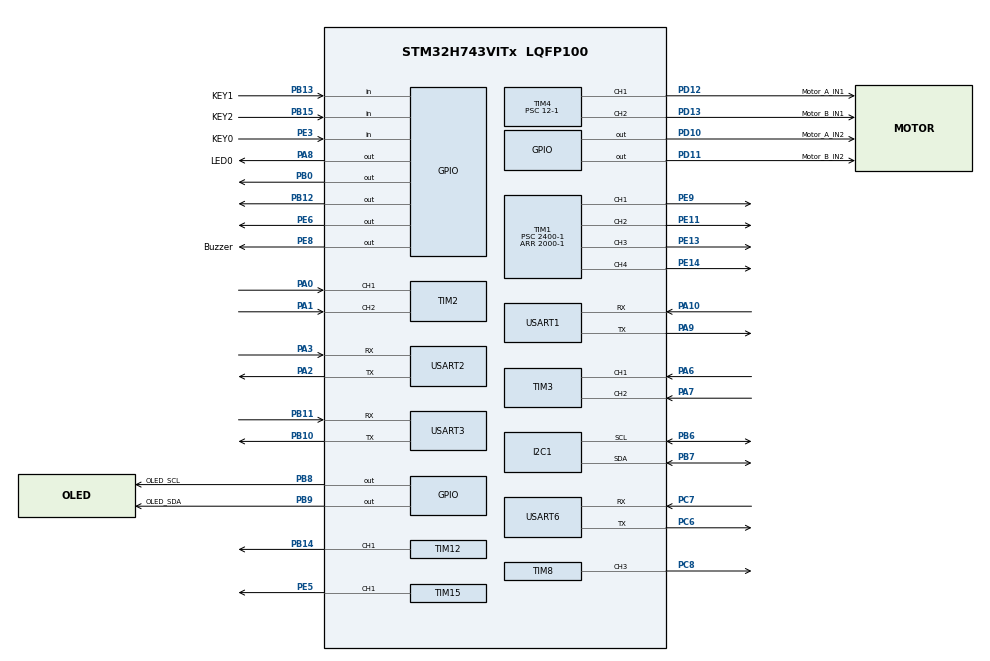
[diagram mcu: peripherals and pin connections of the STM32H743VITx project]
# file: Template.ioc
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CORTEX_M7.AccessPermission-Cortex_Memory_Protection_Unit_Region0_Settings=MPU_REGION_FULL_ACCESS
CORTEX_M7.AccessPermission-Cortex_Memory_Protection_Unit_Region1_Settings=MPU_REGION_FULL_ACCESS
CORTEX_M7.AccessPermission-Cortex_Memory_Protection_Unit_Region2_Settings=MPU_REGION_FULL_ACCESS
CORTEX_M7.AccessPermission-Cortex_Memory_Protection_Unit_Region3_Settings=MPU_REGION_FULL_ACCESS
CORTEX_M7.AccessPermission-Cortex_Memory_Protection_Unit_Region4_Settings=MPU_REGION_FULL_ACCESS
CORTEX_M7.BaseAddress-Cortex_Memory_Protection_Unit_Region0_Settings=0x24000000
CORTEX_M7.BaseAddress-Cortex_Memory_Protection_Unit_Region1_Settings=0x30000000
CORTEX_M7.BaseAddress-Cortex_Memory_Protection_Unit_Region2_Settings=0x30020000
CORTEX_M7.BaseAddress-Cortex_Memory_Protection_Unit_Region3_Settings=0x30040000
CORTEX_M7.BaseAddress-Cortex_Memory_Protection_Unit_Region4_Settings=0x38000000
CORTEX_M7.CPU_DCache=Enabled
CORTEX_M7.CPU_ICache=Enabled
CORTEX_M7.Enable-Cortex_Memory_Protection_Unit_Region0_Settings=MPU_REGION_ENABLE
CORTEX_M7.Enable-Cortex_Memory_Protection_Unit_Region1_Settings=MPU_REGION_ENABLE
CORTEX_M7.Enable-Cortex_Memory_Protection_Unit_Region2_Settings=MPU_REGION_ENABLE
CORTEX_M7.Enable-Cortex_Memory_Protection_Unit_Region3_Settings=MPU_REGION_ENABLE
CORTEX_M7.Enable-Cortex_Memory_Protection_Unit_Region4_Settings=MPU_REGION_ENABLE
CORTEX_M7.IsBufferable-Cortex_Memory_Protection_Unit_Region0_Settings=MPU_ACCESS_BUFFERABLE
CORTEX_M7.IsCacheable-Cortex_Memory_Protection_Unit_Region0_Settings=MPU_ACCESS_CACHEABLE
CORTEX_M7.MPU_Control=MPU_PRIVILEGED_DEFAULT
CORTEX_M7.Size-Cortex_Memory_Protection_Unit_Region0_Settings=MPU_REGION_SIZE_512KB
CORTEX_M7.Size-Cortex_Memory_Protection_Unit_Region1_Settings=MPU_REGION_SIZE_128KB
CORTEX_M7.Size-Cortex_Memory_Protection_Unit_Region2_Settings=MPU_REGION_SIZE_128KB
CORTEX_M7.Size-Cortex_Memory_Protection_Unit_Region3_Settings=MPU_REGION_SIZE_32KB
CORTEX_M7.Size-Cortex_Memory_Protection_Unit_Region4_Settings=MPU_REGION_SIZE_64KB
CORTEX_M7.TypeExtField-Cortex_Memory_Protection_Unit_Region0_Settings=MPU_TEX_LEVEL1
CORTEX_M7.TypeExtField-Cortex_Memory_Protection_Unit_Region1_Settings=MPU_TEX_LEVEL1
CORTEX_M7.TypeExtField-Cortex_Memory_Protection_Unit_Region2_Settings=MPU_TEX_LEVEL1
CORTEX_M7.TypeExtField-Cortex_Memory_Protection_Unit_Region3_Settings=MPU_TEX_LEVEL1
CORTEX_M7.TypeExtField-Cortex_Memory_Protection_Unit_Region4_Settings=MPU_TEX_LEVEL1
Dma.Request0=USART2_RX
Dma.Request1=USART2_TX
Dma.Request2=USART1_RX
Dma.Request3=USART1_TX
Dma.Request4=USART3_RX
Dma.Request5=USART3_TX
Dma.Request6=USART6_RX
Dma.Request7=USART6_TX
Dma.USART1_RX.2.Direction=DMA_PERIPH_TO_MEMORY
Dma.USART1_RX.2.EventEnable=DISABLE
Dma.USART1_RX.2.FIFOMode=DMA_FIFOMODE_DISABLE
Dma.USART1_RX.2.Instance=DMA1_Stream2
Dma.USART1_RX.2.MemDataAlignment=DMA_MDATAALIGN_BYTE
Dma.USART1_RX.2.MemInc=DMA_MINC_ENABLE
Dma.USART1_RX.2.Mode=DMA_NORMAL
Dma.USART1_RX.2.PeriphDataAlignment=DMA_PDATAALIGN_BYTE
Dma.USART1_RX.2.PeriphInc=DMA_PINC_DISABLE
Dma.USART1_RX.2.Polarity=HAL_DMAMUX_REQ_GEN_RISING
Dma.USART1_RX.2.Priority=DMA_PRIORITY_HIGH
Dma.USART1_RX.2.RequestNumber=1
Dma.USART1_RX.2.SignalID=NONE
Dma.USART1_RX.2.SyncEnable=DISABLE
Dma.USART1_RX.2.SyncPolarity=HAL_DMAMUX_SYNC_NO_EVENT
Dma.USART1_RX.2.SyncRequestNumber=1
Dma.USART1_RX.2.SyncSignalID=NONE
Dma.USART1_TX.3.Direction=DMA_MEMORY_TO_PERIPH
Dma.USART1_TX.3.EventEnable=DISABLE
Dma.USART1_TX.3.FIFOMode=DMA_FIFOMODE_DISABLE
Dma.USART1_TX.3.Instance=DMA1_Stream3
Dma.USART1_TX.3.MemDataAlignment=DMA_MDATAALIGN_BYTE
Dma.USART1_TX.3.MemInc=DMA_MINC_ENABLE
Dma.USART1_TX.3.Mode=DMA_NORMAL
Dma.USART1_TX.3.PeriphDataAlignment=DMA_PDATAALIGN_BYTE
Dma.USART1_TX.3.PeriphInc=DMA_PINC_DISABLE
Dma.USART1_TX.3.Polarity=HAL_DMAMUX_REQ_GEN_RISING
Dma.USART1_TX.3.Priority=DMA_PRIORITY_HIGH
Dma.USART1_TX.3.RequestNumber=1
Dma.USART1_TX.3.SignalID=NONE
Dma.USART1_TX.3.SyncEnable=DISABLE
Dma.USART1_TX.3.SyncPolarity=HAL_DMAMUX_SYNC_NO_EVENT
Dma.USART1_TX.3.SyncRequestNumber=1
Dma.USART1_TX.3.SyncSignalID=NONE
Dma.USART2_RX.0.Direction=DMA_PERIPH_TO_MEMORY
Dma.USART2_RX.0.EventEnable=DISABLE
Dma.USART2_RX.0.FIFOMode=DMA_FIFOMODE_DISABLE
Dma.USART2_RX.0.Instance=DMA1_Stream0
Dma.USART2_RX.0.MemDataAlignment=DMA_MDATAALIGN_BYTE
Dma.USART2_RX.0.MemInc=DMA_MINC_ENABLE
Dma.USART2_RX.0.Mode=DMA_NORMAL
Dma.USART2_RX.0.PeriphDataAlignment=DMA_PDATAALIGN_BYTE
Dma.USART2_RX.0.PeriphInc=DMA_PINC_DISABLE
Dma.USART2_RX.0.Polarity=HAL_DMAMUX_REQ_GEN_RISING
Dma.USART2_RX.0.Priority=DMA_PRIORITY_HIGH
Dma.USART2_RX.0.RequestNumber=1
Dma.USART2_RX.0.SignalID=NONE
Dma.USART2_RX.0.SyncEnable=DISABLE
Dma.USART2_RX.0.SyncPolarity=HAL_DMAMUX_SYNC_NO_EVENT
Dma.USART2_RX.0.SyncRequestNumber=1
Dma.USART2_RX.0.SyncSignalID=NONE
Dma.USART2_TX.1.Direction=DMA_MEMORY_TO_PERIPH
Dma.USART2_TX.1.EventEnable=DISABLE
Dma.USART2_TX.1.FIFOMode=DMA_FIFOMODE_DISABLE
Dma.USART2_TX.1.Instance=DMA1_Stream1
Dma.USART2_TX.1.MemDataAlignment=DMA_MDATAALIGN_BYTE
Dma.USART2_TX.1.MemInc=DMA_MINC_ENABLE
Dma.USART2_TX.1.Mode=DMA_NORMAL
Dma.USART2_TX.1.PeriphDataAlignment=DMA_PDATAALIGN_BYTE
Dma.USART2_TX.1.PeriphInc=DMA_PINC_DISABLE
Dma.USART2_TX.1.Polarity=HAL_DMAMUX_REQ_GEN_RISING
Dma.USART2_TX.1.Priority=DMA_PRIORITY_HIGH
Dma.USART2_TX.1.RequestNumber=1
Dma.USART2_TX.1.SignalID=NONE
Dma.USART2_TX.1.SyncEnable=DISABLE
Dma.USART2_TX.1.SyncPolarity=HAL_DMAMUX_SYNC_NO_EVENT
Dma.USART2_TX.1.SyncRequestNumber=1
Dma.USART2_TX.1.SyncSignalID=NONE
Dma.USART3_RX.4.Direction=DMA_PERIPH_TO_MEMORY
Dma.USART3_RX.4.EventEnable=DISABLE
Dma.USART3_RX.4.FIFOMode=DMA_FIFOMODE_DISABLE
Dma.USART3_RX.4.Instance=DMA1_Stream4
Dma.USART3_RX.4.MemDataAlignment=DMA_MDATAALIGN_BYTE
Dma.USART3_RX.4.MemInc=DMA_MINC_ENABLE
Dma.USART3_RX.4.Mode=DMA_NORMAL
Dma.USART3_RX.4.PeriphDataAlignment=DMA_PDATAALIGN_BYTE
Dma.USART3_RX.4.PeriphInc=DMA_PINC_DISABLE
Dma.USART3_RX.4.Polarity=HAL_DMAMUX_REQ_GEN_RISING
Dma.USART3_RX.4.Priority=DMA_PRIORITY_LOW
Dma.USART3_RX.4.RequestNumber=1
Dma.USART3_RX.4.SignalID=NONE
Dma.USART3_RX.4.SyncEnable=DISABLE
Dma.USART3_RX.4.SyncPolarity=HAL_DMAMUX_SYNC_NO_EVENT
Dma.USART3_RX.4.SyncRequestNumber=1
Dma.USART3_RX.4.SyncSignalID=NONE
Dma.USART3_TX.5.Direction=DMA_MEMORY_TO_PERIPH
Dma.USART3_TX.5.EventEnable=DISABLE
Dma.USART3_TX.5.FIFOMode=DMA_FIFOMODE_DISABLE
Dma.USART3_TX.5.Instance=DMA1_Stream5
Dma.USART3_TX.5.MemDataAlignment=DMA_MDATAALIGN_BYTE
Dma.USART3_TX.5.MemInc=DMA_MINC_ENABLE
Dma.USART3_TX.5.Mode=DMA_NORMAL
Dma.USART3_TX.5.PeriphDataAlignment=DMA_PDATAALIGN_BYTE
Dma.USART3_TX.5.PeriphInc=DMA_PINC_DISABLE
Dma.USART3_TX.5.Polarity=HAL_DMAMUX_REQ_GEN_RISING
Dma.USART3_TX.5.Priority=DMA_PRIORITY_LOW
Dma.USART3_TX.5.RequestNumber=1
Dma.USART3_TX.5.SignalID=NONE
Dma.USART3_TX.5.SyncEnable=DISABLE
Dma.USART3_TX.5.SyncPolarity=HAL_DMAMUX_SYNC_NO_EVENT
Dma.USART3_TX.5.SyncRequestNumber=1
Dma.USART3_TX.5.SyncSignalID=NONE
Dma.USART6_RX.6.Direction=DMA_PERIPH_TO_MEMORY
Dma.USART6_RX.6.EventEnable=DISABLE
Dma.USART6_RX.6.FIFOMode=DMA_FIFOMODE_DISABLE
Dma.USART6_RX.6.Instance=DMA1_Stream6
Dma.USART6_RX.6.MemDataAlignment=DMA_MDATAALIGN_BYTE
Dma.USART6_RX.6.MemInc=DMA_MINC_ENABLE
Dma.USART6_RX.6.Mode=DMA_NORMAL
Dma.USART6_RX.6.PeriphDataAlignment=DMA_PDATAALIGN_BYTE
Dma.USART6_RX.6.PeriphInc=DMA_PINC_DISABLE
Dma.USART6_RX.6.Polarity=HAL_DMAMUX_REQ_GEN_RISING
Dma.USART6_RX.6.Priority=DMA_PRIORITY_LOW
Dma.USART6_RX.6.RequestNumber=1
Dma.USART6_RX.6.SignalID=NONE
Dma.USART6_RX.6.SyncEnable=DISABLE
Dma.USART6_RX.6.SyncPolarity=HAL_DMAMUX_SYNC_NO_EVENT
Dma.USART6_RX.6.SyncRequestNumber=1
Dma.USART6_RX.6.SyncSignalID=NONE
Dma.USART6_TX.7.Direction=DMA_MEMORY_TO_PERIPH
Dma.USART6_TX.7.EventEnable=DISABLE
Dma.USART6_TX.7.FIFOMode=DMA_FIFOMODE_DISABLE
Dma.USART6_TX.7.Instance=DMA2_Stream7
Dma.USART6_TX.7.MemDataAlignment=DMA_MDATAALIGN_BYTE
Dma.USART6_TX.7.MemInc=DMA_MINC_ENABLE
Dma.USART6_TX.7.Mode=DMA_NORMAL
Dma.USART6_TX.7.PeriphDataAlignment=DMA_PDATAALIGN_BYTE
Dma.USART6_TX.7.PeriphInc=DMA_PINC_DISABLE
Dma.USART6_TX.7.Polarity=HAL_DMAMUX_REQ_GEN_RISING
Dma.USART6_TX.7.Priority=DMA_PRIORITY_LOW
Dma.USART6_TX.7.RequestNumber=1
Dma.USART6_TX.7.SignalID=NONE
Dma.USART6_TX.7.SyncEnable=DISABLE
Dma.USART6_TX.7.SyncPolarity=HAL_DMAMUX_SYNC_NO_EVENT
Dma.USART6_TX.7.SyncRequestNumber=1
Dma.USART6_TX.7.SyncSignalID=NONE
I2C1.Timing=0x307075B1
Mcu.Family=STM32H7
Mcu.Name=STM32H743VITx
Mcu.Package=LQFP100
NVIC.DMA1_Stream0_IRQn=true\:0\:0\:false\:false\:true\:false\:true\:true
NVIC.DMA1_Stream1_IRQn=true\:0\:0\:false\:false\:true\:false\:true\:true
NVIC.DMA1_Stream2_IRQn=true\:0\:0\:false\:false\:true\:false\:true\:true
NVIC.DMA1_Stream3_IRQn=true\:0\:0\:false\:false\:true\:false\:true\:true
NVIC.DMA1_Stream4_IRQn=true\:0\:0\:false\:false\:true\:false\:true\:true
NVIC.DMA1_Stream5_IRQn=true\:0\:0\:false\:false\:true\:false\:true\:true
NVIC.DMA1_Stream6_IRQn=true\:0\:0\:false\:false\:true\:false\:true\:true
NVIC.DMA2_Stream7_IRQn=true\:0\:0\:false\:false\:true\:false\:true\:true
NVIC.PriorityGroup=NVIC_PRIORITYGROUP_4
NVIC.TIM15_IRQn=true\:0\:0\:false\:false\:true\:true\:true\:true
NVIC.TIM16_IRQn=true\:0\:0\:false\:false\:true\:true\:true\:true
NVIC.TIM17_IRQn=true\:0\:0\:false\:false\:true\:true\:true\:true
NVIC.TIM6_DAC_IRQn=true\:0\:0\:false\:false\:true\:true\:true\:true
NVIC.TIM8_BRK_TIM12_IRQn=true\:0\:0\:false\:false\:true\:true\:true\:true
NVIC.USART1_IRQn=true\:0\:0\:false\:false\:true\:true\:true\:true
NVIC.USART2_IRQn=true\:0\:0\:false\:false\:true\:true\:true\:true
NVIC.USART3_IRQn=true\:0\:0\:false\:false\:true\:true\:true\:true
NVIC.USART6_IRQn=true\:0\:0\:false\:false\:true\:true\:true\:true
PA0.Signal=S_TIM2_CH1_ETR
PA1.Signal=S_TIM2_CH2
PA10.Mode=Asynchronous
PA10.Signal=USART1_RX
PA13\ (JTMS/SWDIO).Mode=Serial_Wire
PA13\ (JTMS/SWDIO).Signal=DEBUG_JTMS-SWDIO
PA14\ (JTCK/SWCLK).Mode=Serial_Wire
PA14\ (JTCK/SWCLK).Signal=DEBUG_JTCK-SWCLK
PA2.Mode=Asynchronous
PA2.Signal=USART2_TX
PA3.Mode=Asynchronous
PA3.Signal=USART2_RX
PA6.Signal=S_TIM3_CH1
PA7.Signal=S_TIM3_CH2
PA8.GPIO_Label=LED0
PA8.GPIO_ModeDefaultOutputPP=GPIO_MODE_OUTPUT_PP
PA8.GPIO_PuPd=GPIO_NOPULL
PA8.GPIO_Speed=GPIO_SPEED_FREQ_LOW
PA8.PinState=GPIO_PIN_RESET
PA8.Signal=GPIO_Output
PA9.Mode=Asynchronous
PA9.Signal=USART1_TX
PB0.PinState=GPIO_PIN_SET
PB0.Signal=GPIO_Output
PB10.Mode=Asynchronous
PB10.Signal=USART3_TX
PB11.Mode=Asynchronous
PB11.Signal=USART3_RX
PB12.GPIO_Speed=GPIO_SPEED_FREQ_HIGH
PB12.Signal=GPIO_Output
PB13.GPIO_Label=KEY1
PB13.GPIO_PuPd=GPIO_PULLUP
PB13.Signal=GPIO_Input
PB14.Signal=S_TIM12_CH1
PB15.GPIO_Label=KEY2
PB15.GPIO_PuPd=GPIO_PULLUP
PB15.Signal=GPIO_Input
PB6.Mode=I2C
PB6.Signal=I2C1_SCL
PB7.Mode=I2C
PB7.Signal=I2C1_SDA
PB8.GPIO_FM8=__NULL
PB8.GPIO_Label=OLED_SCL
PB8.GPIO_ModeDefaultOutputPP=GPIO_MODE_OUTPUT_PP
PB8.GPIO_PuPd=GPIO_NOPULL
PB8.GPIO_Speed=GPIO_SPEED_FREQ_HIGH
PB8.PinState=GPIO_PIN_RESET
PB8.Signal=GPIO_Output
PB9.GPIO_FM9=__NULL
PB9.GPIO_Label=OLED_SDA
PB9.GPIO_ModeDefaultOutputPP=GPIO_MODE_OUTPUT_PP
PB9.GPIO_PuPd=GPIO_NOPULL
PB9.GPIO_Speed=GPIO_SPEED_FREQ_HIGH
PB9.PinState=GPIO_PIN_RESET
PB9.Signal=GPIO_Output
PC6.Mode=Asynchronous
PC6.Signal=USART6_TX
PC7.Mode=Asynchronous
PC7.Signal=USART6_RX
PC8.Signal=S_TIM8_CH3
PD10.GPIO_Label=Motor_A_IN2
PD10.Signal=GPIO_Output
PD11.GPIO_Label=Motor_B_IN2
PD11.Signal=GPIO_Output
PD12.GPIO_Label=Motor_A_IN1
PD12.Signal=S_TIM4_CH1
PD13.GPIO_Label=Motor_B_IN1
PD13.Signal=S_TIM4_CH2
PE11.Signal=S_TIM1_CH2
PE13.Signal=S_TIM1_CH3
PE14.Signal=S_TIM1_CH4
PE3.GPIO_Label=KEY0
PE3.GPIO_PuPd=GPIO_PULLUP
PE3.Signal=GPIO_Input
PE5.Signal=S_TIM15_CH1
PE6.GPIO_Speed=GPIO_SPEED_FREQ_HIGH
PE6.Signal=GPIO_Output
PE8.GPIO_Label=Buzzer
PE8.PinState=GPIO_PIN_SET
PE8.Signal=GPIO_Output
PE9.Signal=S_TIM1_CH1
PH0-OSC_IN\ (PH0).Mode=HSE-External-Oscillator
PH0-OSC_IN\ (PH0).Signal=RCC_OSC_IN
PH1-OSC_OUT\ (PH1).Mode=HSE-External-Oscillator
PH1-OSC_OUT\ (PH1).Signal=RCC_OSC_OUT
ProjectManager.HeapSize=0x200
ProjectManager.StackSize=0x7400
ProjectManager.TargetToolchain=MDK-ARM V5.32
RCC.ADCFreq_Value=50390625
RCC.APB1Freq_Value=120000000
RCC.APB2Freq_Value=120000000
RCC.APB3Freq_Value=120000000
RCC.APB4Freq_Value=120000000
RCC.CortexFreq_Value=240000000
RCC.D1PPRE=RCC_APB3_DIV2
RCC.D2PPRE1=RCC_APB1_DIV2
RCC.D2PPRE2=RCC_APB2_DIV2
RCC.D3PPRE=RCC_APB4_DIV2
RCC.DIVM1=5
RCC.DIVN1=96
RCC.HCLKFreq_Value=240000000
RCC.HSE_VALUE=25000000
RCC.PLLFRACN=0
RCC.PLLSourceVirtual=RCC_PLLSOURCE_HSE
RCC.PWR_Regulator_Voltage_Scale=PWR_REGULATOR_VOLTAGE_SCALE0
RCC.ProductRev=revV
RCC.SYSCLKFreq_VALUE=240000000
RCC.SYSCLKSource=RCC_SYSCLKSOURCE_PLLCLK
RCC.USBFreq_Value=240000000
SH.S_TIM12_CH1.0=TIM12_CH1,PWM Generation1 CH1
SH.S_TIM15_CH1.0=TIM15_CH1,PWM Generation1 CH1
SH.S_TIM1_CH1.0=TIM1_CH1,PWM Generation1 CH1
SH.S_TIM1_CH2.0=TIM1_CH2,PWM Generation2 CH2
SH.S_TIM1_CH3.0=TIM1_CH3,PWM Generation3 CH3
SH.S_TIM1_CH4.0=TIM1_CH4,PWM Generation4 CH4
SH.S_TIM2_CH1_ETR.0=TIM2_CH1,Encoder_Interface
SH.S_TIM2_CH2.0=TIM2_CH2,Encoder_Interface
SH.S_TIM3_CH1.0=TIM3_CH1,Encoder_Interface
SH.S_TIM3_CH2.0=TIM3_CH2,Encoder_Interface
SH.S_TIM4_CH1.0=TIM4_CH1,PWM Generation1 CH1
SH.S_TIM4_CH2.0=TIM4_CH2,PWM Generation2 CH2
SH.S_TIM8_CH3.0=TIM8_CH3,PWM Generation3 CH3
TIM1.AutoReloadPreload=TIM_AUTORELOAD_PRELOAD_ENABLE
TIM1.Channel-PWM\ Generation1\ CH1=TIM_CHANNEL_1
TIM1.Channel-PWM\ Generation2\ CH2=TIM_CHANNEL_2
TIM1.Channel-PWM\ Generation3\ CH3=TIM_CHANNEL_3
TIM1.Channel-PWM\ Generation4\ CH4=TIM_CHANNEL_4
TIM1.Period=2000-1
TIM1.Prescaler=2400-1
TIM12.AutoReloadPreload=TIM_AUTORELOAD_PRELOAD_ENABLE
TIM12.Channel-PWM\ Generation1\ CH1=TIM_CHANNEL_1
TIM12.Period=1000-1
TIM12.Prescaler=240-1
TIM15.AutoReloadPreload=TIM_AUTORELOAD_PRELOAD_ENABLE
TIM15.Channel-PWM\ Generation1\ CH1=TIM_CHANNEL_1
TIM15.Period=1000-1
TIM15.Prescaler=240-1
TIM16.Period=20000-1
TIM16.Prescaler=240-1
TIM17.Period=1000-1
TIM17.Prescaler=240-1
TIM2.EncoderMode=TIM_ENCODERMODE_TI12
TIM3.EncoderMode=TIM_ENCODERMODE_TI12
TIM4.AutoReloadPreload=TIM_AUTORELOAD_PRELOAD_ENABLE
TIM4.Channel-PWM\ Generation1\ CH1=TIM_CHANNEL_1
TIM4.Channel-PWM\ Generation2\ CH2=TIM_CHANNEL_2
TIM4.Period=1000-1
TIM4.Prescaler=12-1
TIM6.AutoReloadPreload=TIM_AUTORELOAD_PRELOAD_ENABLE
TIM6.Period=5000-1
TIM6.Prescaler=240-1
TIM7.AutoReloadPreload=TIM_AUTORELOAD_PRELOAD_ENABLE
TIM7.Prescaler=240-1
TIM8.AutoReloadPreload=TIM_AUTORELOAD_PRELOAD_ENABLE
TIM8.Channel-PWM\ Generation3\ CH3=TIM_CHANNEL_3
TIM8.Period=2000-1
TIM8.Prescaler=2400-1
USART1.VirtualMode-Asynchronous=VM_ASYNC
USART2.VirtualMode-Asynchronous=VM_ASYNC
USART3.VirtualMode-Asynchronous=VM_ASYNC
USART6.VirtualMode=VM_ASYNC
VP_MEMORYMAP_VS_MEMORYMAP.Mode=CurAppReg
VP_TIM12_VS_ClockSourceINT.Mode=Internal
VP_TIM15_VS_ClockSourceINT.Mode=Internal
VP_TIM16_VS_ClockSourceINT.Mode=Enable_Timer
VP_TIM17_VS_ClockSourceINT.Mode=Enable_Timer
VP_TIM1_VS_ClockSourceINT.Mode=Internal
VP_TIM4_VS_ClockSourceINT.Mode=Internal
VP_TIM6_VS_ClockSourceINT.Mode=Enable_Timer
VP_TIM7_VS_ClockSourceINT.Mode=Enable_Timer
VP_TIM8_VS_ClockSourceINT.Mode=Internal
board=custom

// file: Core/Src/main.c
/* USER CODE BEGIN Header */
/**
  ******************************************************************************
  * @file           : main.c
  * @brief          : Main program body
  ******************************************************************************
  * @attention
  *
  * Copyright (c) 2023 STMicroelectronics.
  * All rights reserved.
  *
  * This software is licensed under terms that can be found in the LICENSE file
  * in the root directory of this software component.
  * If no LICENSE file comes with this software, it is provided AS-IS.
  *
  ******************************************************************************
  */
/* USER CODE END Header */
#include "main.h"
#include "dma.h"
#include "i2c.h"
#include "tim.h"
#include "usart.h"
#include "gpio.h"

/* USER CODE BEGIN Includes */
#include "Mymain.h"
#include "AllHeader.h"
/* USER CODE END Includes */

void SystemClock_Config(void);
static void MPU_Config(void);

int main(void)
{

  /* MPU Configuration--------------------------------------------------------*/
  MPU_Config();

  /* Enable the CPU Cache */

  /* Enable I-Cache---------------------------------------------------------*/
  SCB_EnableICache();

  /* Enable D-Cache---------------------------------------------------------*/
  SCB_EnableDCache();

  /* MCU Configuration--------------------------------------------------------*/

  /* Reset of all peripherals, Initializes the Flash interface and the Systick. */
  HAL_Init();

  /* Configure the system clock */
  SystemClock_Config();

  /* Initialize all configured peripherals */
  MX_GPIO_Init();
  MX_DMA_Init();
  MX_USART1_UART_Init();
  MX_TIM2_Init();
  MX_TIM3_Init();
  MX_TIM16_Init();
  MX_TIM17_Init();
  MX_TIM7_Init();
  MX_USART2_UART_Init();
  MX_TIM1_Init();
  MX_TIM4_Init();
  MX_TIM8_Init();
  MX_I2C1_Init();
  MX_USART3_UART_Init();
  MX_TIM6_Init();
  MX_USART6_UART_Init();
  MX_TIM12_Init();
  MX_TIM15_Init();
  /* USER CODE BEGIN 2 */
	Mymain() ;
  /* USER CODE END 2 */

  /* Infinite loop */
  while (1)
  {

  }
}

void SystemClock_Config(void)
{
  RCC_OscInitTypeDef RCC_OscInitStruct = {0};
  RCC_ClkInitTypeDef RCC_ClkInitStruct = {0};

  /** Supply configuration update enable
  */
  HAL_PWREx_ConfigSupply(PWR_LDO_SUPPLY);

  /** Configure the main internal regulator output voltage
  */
  __HAL_PWR_VOLTAGESCALING_CONFIG(PWR_REGULATOR_VOLTAGE_SCALE0);

  while(!__HAL_PWR_GET_FLAG(PWR_FLAG_VOSRDY)) {}

  /** Initializes the RCC Oscillators according to the specified parameters
  * in the RCC_OscInitTypeDef structure.
  */
  RCC_OscInitStruct.OscillatorType = RCC_OSCILLATORTYPE_HSE;
  RCC_OscInitStruct.HSEState = RCC_HSE_ON;
  RCC_OscInitStruct.PLL.PLLState = RCC_PLL_ON;
  RCC_OscInitStruct.PLL.PLLSource = RCC_PLLSOURCE_HSE;
  RCC_OscInitStruct.PLL.PLLM = 5;
  RCC_OscInitStruct.PLL.PLLN = 96;
  RCC_OscInitStruct.PLL.PLLP = 2;
  RCC_OscInitStruct.PLL.PLLQ = 2;
  RCC_OscInitStruct.PLL.PLLR = 2;
  RCC_OscInitStruct.PLL.PLLRGE = RCC_PLL1VCIRANGE_2;
  RCC_OscInitStruct.PLL.PLLVCOSEL = RCC_PLL1VCOWIDE;
  RCC_OscInitStruct.PLL.PLLFRACN = 0;
  if (HAL_RCC_OscConfig(&RCC_OscInitStruct) != HAL_OK)
  {
    Error_Handler();
  }

  /** Initializes the CPU, AHB and APB buses clocks
  */
  RCC_ClkInitStruct.ClockType = RCC_CLOCKTYPE_HCLK|RCC_CLOCKTYPE_SYSCLK
                              |RCC_CLOCKTYPE_PCLK1|RCC_CLOCKTYPE_PCLK2
                              |RCC_CLOCKTYPE_D3PCLK1|RCC_CLOCKTYPE_D1PCLK1;
  RCC_ClkInitStruct.SYSCLKSource = RCC_SYSCLKSOURCE_PLLCLK;
  RCC_ClkInitStruct.SYSCLKDivider = RCC_SYSCLK_DIV1;
  RCC_ClkInitStruct.AHBCLKDivider = RCC_HCLK_DIV1;
  RCC_ClkInitStruct.APB3CLKDivider = RCC_APB3_DIV2;
  RCC_ClkInitStruct.APB1CLKDivider = RCC_APB1_DIV2;
  RCC_ClkInitStruct.APB2CLKDivider = RCC_APB2_DIV2;
  RCC_ClkInitStruct.APB4CLKDivider = RCC_APB4_DIV2;

  if (HAL_RCC_ClockConfig(&RCC_ClkInitStruct, FLASH_LATENCY_4) != HAL_OK)
  {
    Error_Handler();
  }
}

 /* MPU Configuration */

void MPU_Config(void)
{
  MPU_Region_InitTypeDef MPU_InitStruct = {0};

  /* Disables the MPU */
  HAL_MPU_Disable();

  /** Initializes and configures the Region and the memory to be protected
  */
  MPU_InitStruct.Enable = MPU_REGION_ENABLE;
  MPU_InitStruct.Number = MPU_REGION_NUMBER0;
  MPU_InitStruct.BaseAddress = 0x24000000;
  MPU_InitStruct.Size = MPU_REGION_SIZE_512KB;
  MPU_InitStruct.SubRegionDisable = 0x0;
  MPU_InitStruct.TypeExtField = MPU_TEX_LEVEL1;
  MPU_InitStruct.AccessPermission = MPU_REGION_FULL_ACCESS;
  MPU_InitStruct.DisableExec = MPU_INSTRUCTION_ACCESS_ENABLE;
  MPU_InitStruct.IsShareable = MPU_ACCESS_NOT_SHAREABLE;
  MPU_InitStruct.IsCacheable = MPU_ACCESS_CACHEABLE;
  MPU_InitStruct.IsBufferable = MPU_ACCESS_BUFFERABLE;

  HAL_MPU_ConfigRegion(&MPU_InitStruct);

  /** Initializes and configures the Region and the memory to be protected
  */
  MPU_InitStruct.Number = MPU_REGION_NUMBER1;
  MPU_InitStruct.BaseAddress = 0x30000000;
  MPU_InitStruct.Size = MPU_REGION_SIZE_128KB;
  MPU_InitStruct.IsCacheable = MPU_ACCESS_NOT_CACHEABLE;
  MPU_InitStruct.IsBufferable = MPU_ACCESS_NOT_BUFFERABLE;

  HAL_MPU_ConfigRegion(&MPU_InitStruct);

  /** Initializes and configures the Region and the memory to be protected
  */
  MPU_InitStruct.Number = MPU_REGION_NUMBER2;
  MPU_InitStruct.BaseAddress = 0x30020000;

  HAL_MPU_ConfigRegion(&MPU_InitStruct);

  /** Initializes and configures the Region and the memory to be protected
  */
  MPU_InitStruct.Number = MPU_REGION_NUMBER3;
  MPU_InitStruct.BaseAddress = 0x30040000;
  MPU_InitStruct.Size = MPU_REGION_SIZE_32KB;

  HAL_MPU_ConfigRegion(&MPU_InitStruct);

  /** Initializes and configures the Region and the memory to be protected
  */
  MPU_InitStruct.Number = MPU_REGION_NUMBER4;
  MPU_InitStruct.BaseAddress = 0x38000000;
  MPU_InitStruct.Size = MPU_REGION_SIZE_64KB;

  HAL_MPU_ConfigRegion(&MPU_InitStruct);
  /* Enables the MPU */
  HAL_MPU_Enable(MPU_PRIVILEGED_DEFAULT);

}

void Error_Handler(void)
{
  __disable_irq();
  while (1)
  {
  }
}
